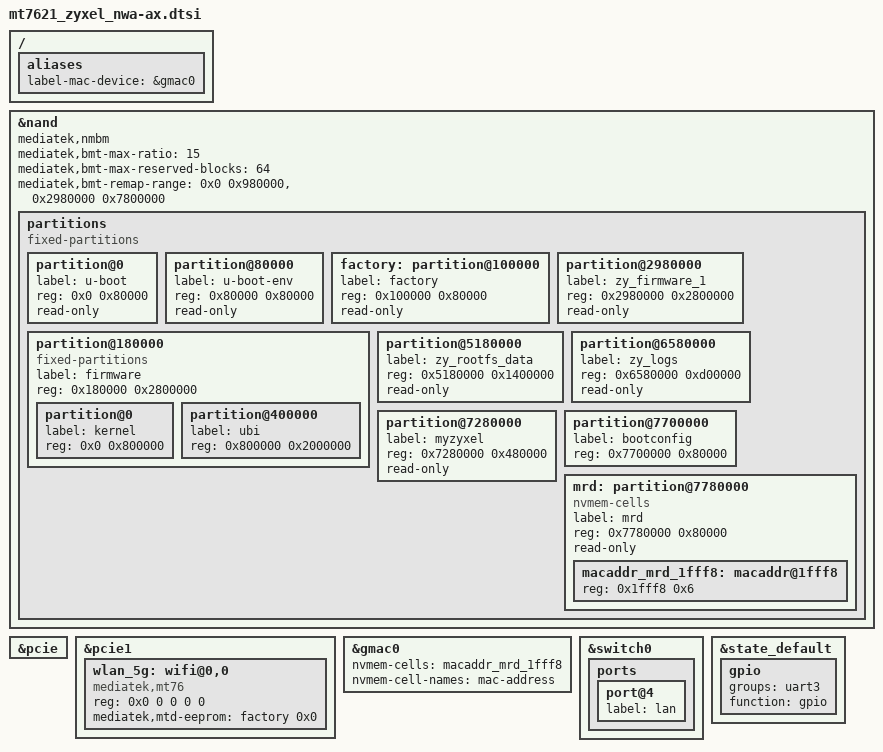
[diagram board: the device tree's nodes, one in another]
#include "mt7621.dtsi"

#include <dt-bindings/gpio/gpio.h>
#include <dt-bindings/input/input.h>

/ {
	aliases {
		label-mac-device = &gmac0;
	};
};

&nand {
	status = "okay";

	mediatek,nmbm;
	mediatek,bmt-max-ratio = <15>;
	mediatek,bmt-max-reserved-blocks = <64>;
	mediatek,bmt-remap-range =
		<0x0 0x980000>,
		<0x2980000 0x7800000>;

	partitions {
		compatible = "fixed-partitions";
		#address-cells = <1>;
		#size-cells = <1>;

		partition@0 {
			label = "u-boot";
			reg = <0x0 0x80000>;
			read-only;
		};

		partition@80000 {
			label = "u-boot-env";
			reg = <0x80000 0x80000>;
			read-only;
		};

		factory: partition@100000 {
			label = "factory";
			reg = <0x100000 0x80000>;
			read-only;
		};

		partition@180000 {
			label = "firmware";
			reg = <0x180000 0x2800000>;

			/* This concatenates kernel1 & kernel2 & rootfs */

			compatible = "fixed-partitions";
			#address-cells = <1>;
			#size-cells = <1>;

			partition@0 {
				label = "kernel";
				reg = <0x0 0x800000>;
			};

			partition@400000 {
				label = "ubi";
				reg = <0x800000 0x2000000>;
			};
		};

		partition@2980000 {
			label = "zy_firmware_1";
			reg = <0x2980000 0x2800000>;
			read-only;
		};

		partition@5180000 {
			label = "zy_rootfs_data";
			reg = <0x5180000 0x1400000>;
			read-only;
		};

		partition@6580000 {
			label = "zy_logs";
			reg = <0x6580000 0xd00000>;
			read-only;
		};

		partition@7280000 {
			label = "myzyxel";
			reg = <0x7280000 0x480000>;
			read-only;
		};

		partition@7700000 {
			label = "bootconfig";
			reg = <0x7700000 0x80000>;
		};

		mrd: partition@7780000 {
			label = "mrd";
			reg = <0x7780000 0x80000>;
			read-only;
		};
	};
};

&pcie {
	status = "okay";
};

&pcie1 {
	wlan_5g: wifi@0,0 {
		reg = <0x0 0 0 0 0>;
		compatible = "mediatek,mt76";

		mediatek,mtd-eeprom = <&factory 0x0>;

		/* MAC-Address set in userspace */
	};
};

&gmac0 {
	nvmem-cells = <&macaddr_mrd_1fff8>;
	nvmem-cell-names = "mac-address";
};

&switch0 {
	ports {
		port@4 {
			status = "okay";
			label = "lan";
		};
	};
};

&mrd {
	compatible = "nvmem-cells";
	#address-cells = <1>;
	#size-cells = <1>;

	macaddr_mrd_1fff8: macaddr@1fff8 {
		reg = <0x1fff8 0x6>;
	};
};

&state_default {
	gpio {
		groups = "uart3";
		function = "gpio";
	};
};
